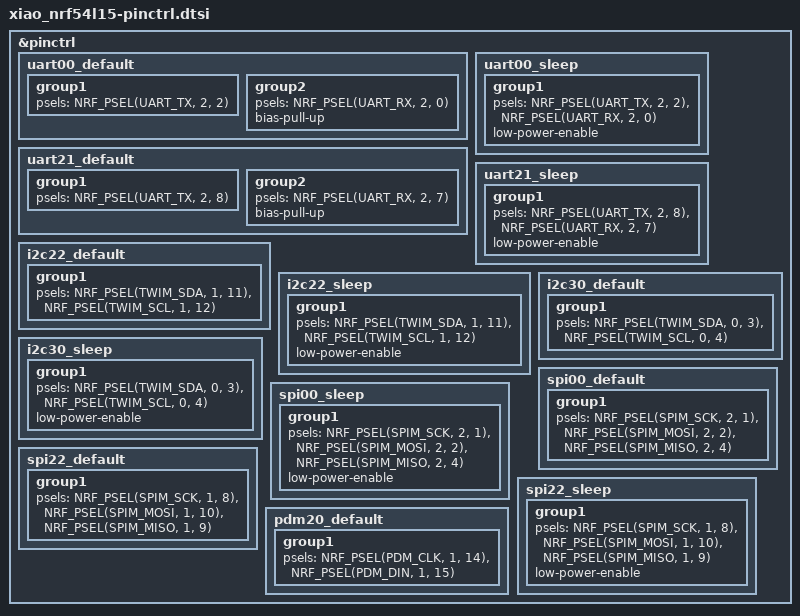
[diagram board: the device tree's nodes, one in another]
&pinctrl {
	/omit-if-no-ref/ uart00_default: uart00_default {
		group1 {
			psels = <NRF_PSEL(UART_TX, 2, 2)>;
		};
		group2 {
			psels = <NRF_PSEL(UART_RX, 2, 0)>;
			bias-pull-up;
		};
	};

	/omit-if-no-ref/ uart00_sleep: uart00_sleep {
		group1 {
			psels = <NRF_PSEL(UART_TX, 2, 2)>,
				<NRF_PSEL(UART_RX, 2, 0)>;
			low-power-enable;
		};
	};

	/omit-if-no-ref/ uart21_default: uart21_default {
		group1 {
			psels = <NRF_PSEL(UART_TX, 2, 8)>;
		};
		group2 {
			psels = <NRF_PSEL(UART_RX, 2, 7)>;
			bias-pull-up;
		};
	};

	/omit-if-no-ref/ uart21_sleep: uart21_sleep {
		group1 {
			psels = <NRF_PSEL(UART_TX, 2, 8)>,
				<NRF_PSEL(UART_RX, 2, 7)>;
			low-power-enable;
		};
	};

	/omit-if-no-ref/ i2c22_default: i2c22_default {
		group1 {
			psels = <NRF_PSEL(TWIM_SDA, 1, 11)>,
				<NRF_PSEL(TWIM_SCL, 1, 12)>;
		};
	};

	/omit-if-no-ref/ i2c22_sleep: i2c22_sleep {
		group1 {
			psels = <NRF_PSEL(TWIM_SDA, 1, 11)>,
				<NRF_PSEL(TWIM_SCL, 1, 12)>;
			low-power-enable;
		};
	};

	/omit-if-no-ref/ i2c30_default: i2c30_default {
		group1 {
			psels = <NRF_PSEL(TWIM_SDA, 0, 3)>,
				<NRF_PSEL(TWIM_SCL, 0, 4)>;
		};
	};

	/omit-if-no-ref/ i2c30_sleep: i2c30_sleep {
		group1 {
			psels = <NRF_PSEL(TWIM_SDA, 0, 3)>,
				<NRF_PSEL(TWIM_SCL, 0, 4)>;
			low-power-enable;
		};
	};
	/omit-if-no-ref/ spi00_default: spi00_default {
		group1 {
			psels = <NRF_PSEL(SPIM_SCK, 2, 1)>,
				<NRF_PSEL(SPIM_MOSI, 2, 2)>,
				<NRF_PSEL(SPIM_MISO, 2, 4)>;
		};
	};

	/omit-if-no-ref/ spi00_sleep: spi00_sleep {
		group1 {
			psels = <NRF_PSEL(SPIM_SCK, 2, 1)>,
				<NRF_PSEL(SPIM_MOSI, 2, 2)>,
				<NRF_PSEL(SPIM_MISO, 2, 4)>;
				low-power-enable;
		};
	};

	/omit-if-no-ref/ spi22_default: spi22_default {
		group1 {
			psels = <NRF_PSEL(SPIM_SCK, 1, 8)>,
				<NRF_PSEL(SPIM_MOSI, 1, 10)>,
				<NRF_PSEL(SPIM_MISO, 1, 9)>;
		};
	};

	/omit-if-no-ref/ spi22_sleep: spi22_sleep {
		group1 {
			psels = <NRF_PSEL(SPIM_SCK, 1, 8)>,
				<NRF_PSEL(SPIM_MOSI, 1, 10)>,
				<NRF_PSEL(SPIM_MISO, 1, 9)>;
				low-power-enable;
		};
	};

	pdm20_default: pdm20_default {
		group1 {
			psels = <NRF_PSEL(PDM_CLK, 1, 14)>,
				<NRF_PSEL(PDM_DIN, 1, 15)>;
		};
	};
};
